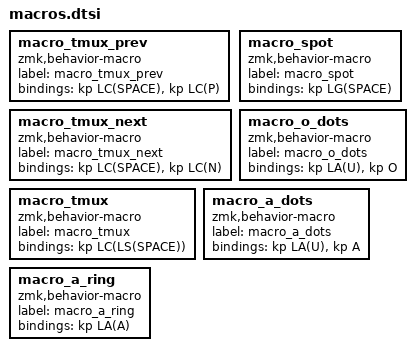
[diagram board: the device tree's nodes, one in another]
macro_tmux_prev: macro_tmux_prev{
compatible = "zmk,behavior-macro";
label = "macro_tmux_prev";
#binding-cells = <0>;
bindings = <&kp LC(SPACE)>, <&kp LC(P)>;
};
macro_tmux_next: macro_tmux_next{
compatible = "zmk,behavior-macro";
label = "macro_tmux_next";
#binding-cells = <0>;
bindings = <&kp LC(SPACE)>, <&kp LC(N)>;
};
macro_spot: macro_spot{
compatible = "zmk,behavior-macro";
label = "macro_spot";
#binding-cells = <0>;
bindings = <&kp LG(SPACE)>;
};
macro_tmux: macro_tmux{
compatible = "zmk,behavior-macro";
label = "macro_tmux";
#binding-cells = <0>;
bindings = <&kp LC(LS(SPACE))>;
};
macro_o_dots: macro_o_dots{
compatible = "zmk,behavior-macro";
label = "macro_o_dots";
#binding-cells = <0>;
bindings = <&kp LA(U)>, <&kp O>;
};
macro_a_dots: macro_a_dots{
compatible = "zmk,behavior-macro";
label = "macro_a_dots";
#binding-cells = <0>;
bindings = <&kp LA(U)>, <&kp A>;
};
macro_a_ring: macro_a_ring{
compatible = "zmk,behavior-macro";
label = "macro_a_ring";
#binding-cells = <0>;
bindings = <&kp LA(A)>;
};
